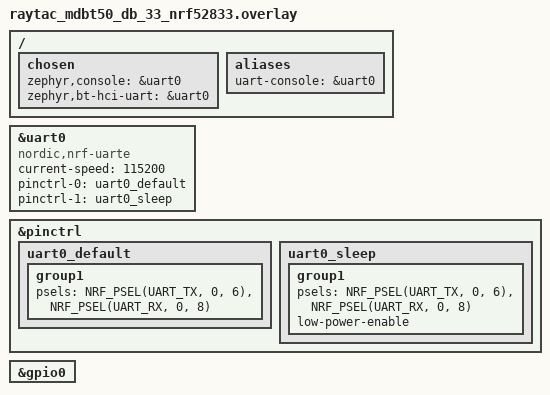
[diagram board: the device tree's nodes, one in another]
/*
 * Overlay for Raytac MDBT50-DB-33 (nRF52833)
 * Enables UART0 for console and Bluetooth HCI
 * Configures GPIO for DW3000 (if needed)
 */

/ {
    /* Chosen nodes for console and Bluetooth */
    chosen {
        zephyr,console = &uart0;        /* UART0 for console output */
        zephyr,bt-hci-uart = &uart0;    /* UART0 for Bluetooth HCI */
    };

    /* Alias for easier reference (optional) */
    aliases {
        uart-console = &uart0;
    };
};

/* Enable and configure UART0 */
&uart0 {
    status = "okay";
    compatible = "nordic,nrf-uarte";
    current-speed = <115200>;           /* Baud rate */
    pinctrl-0 = <&uart0_default>;       /* Default pin configuration */
    pinctrl-1 = <&uart0_sleep>;         /* Sleep pin configuration */
    pinctrl-names = "default", "sleep";
};

/* Pin control configuration */
&pinctrl {
    /* UART0 default pins (adjust if your board uses different pins) */
    uart0_default: uart0_default {
        group1 {
            psels = <NRF_PSEL(UART_TX, 0, 6)>,  /* P0.06 as TXD */
                    <NRF_PSEL(UART_RX, 0, 8)>;  /* P0.08 as RXD */
        };
    };

    uart0_sleep: uart0_sleep {
        group1 {
            psels = <NRF_PSEL(UART_TX, 0, 6)>,
                    <NRF_PSEL(UART_RX, 0, 8)>;
            low-power-enable;
        };
    };
};

/* Ensure GPIO0 is enabled (for DW3000 pins) */
&gpio0 {
    status = "okay";
};

/* Optional: Define DW3000 pins explicitly (uncomment if needed) */
/*
&dwm3000 {
    status = "okay";
    compatible = "qorvo,dwm3000";
    irq-gpios = <&gpio0 3 0>;    // P0.03
    wakeup-gpios = <&gpio0 29 0>; // P0.29
    reset-gpios = <&gpio0 28 0>;  // P0.28
    rx-led-gpios = <&gpio0 6 0>;  // P0.06
    tx-led-gpios = <&gpio0 7 0>;  // P0.07
    spi-pol-gpios = <&gpio0 8 0>; // P0.08
    spi-pha-gpios = <&gpio0 9 0>; // P0.09
};
*/
